VERSION ""

NS_ :

BS_:

BU_: CH DIPF DIPR ETH FC HVI HVS PARTY SDCV VEH VIRT

BO_ 962 VCLEFT_switchStatus: 8 CH
 SG_ VCLEFT_rearHVACButtonPressed m0 : 61|1@1+ (1,0) [0|1] ""  X
 SG_ VCLEFT_brakePressed m0 : 60|1@1+ (1,0) [0|1] ""  X
 SG_ VCLEFT_rearRightOccupancySwitch m0 : 58|2@1+ (1,0) [0|3] ""  X
 SG_ VCLEFT_rearLeftOccupancySwitch m0 : 56|2@1+ (1,0) [0|3] ""  X
 SG_ VCLEFT_rearCenterOccupancySwitch m0 : 54|2@1+ (1,0) [0|3] ""  X
 SG_ VCLEFT_rearLeftBuckleSwitch m0 : 52|2@1+ (1,0) [0|3] ""  X
 SG_ VCLEFT_frontOccupancySwitch m0 : 50|2@1+ (1,0) [0|3] ""  X
 SG_ VCLEFT_frontBuckleSwitch m0 : 48|2@1+ (1,0) [0|3] ""  ocs1p
 SG_ VCLEFT_btnWindowSwPackAutoDownRR m0 : 47|1@1+ (1,0) [0|1] ""  X
 SG_ VCLEFT_btnWindowSwPackDownRR m0 : 46|1@1+ (1,0) [0|1] ""  X
 SG_ VCLEFT_btnWindowSwPackAutoUpRR m0 : 45|1@1+ (1,0) [0|1] ""  X
 SG_ VCLEFT_btnWindowSwPackUpRR m0 : 44|1@1+ (1,0) [0|1] ""  X
 SG_ VCLEFT_btnWindowSwPackAutoDownRF m0 : 43|1@1+ (1,0) [0|1] ""  X
 SG_ VCLEFT_btnWindowSwPackDownRF m0 : 42|1@1+ (1,0) [0|1] ""  X
 SG_ VCLEFT_btnWindowSwPackAutoUpRF m0 : 41|1@1+ (1,0) [0|1] ""  X
 SG_ VCLEFT_btnWindowSwPackUpRF m0 : 40|1@1+ (1,0) [0|1] ""  X
 SG_ VCLEFT_btnWindowSwPackAutoDownLR m0 : 39|1@1+ (1,0) [0|1] ""  X
 SG_ VCLEFT_btnWindowSwPackDownLR m0 : 38|1@1+ (1,0) [0|1] ""  X
 SG_ VCLEFT_btnWindowSwPackAutoUpLR m0 : 37|1@1+ (1,0) [0|1] ""  X
 SG_ VCLEFT_btnWindowSwPackUpLR m0 : 36|1@1+ (1,0) [0|1] ""  X
 SG_ VCLEFT_btnWindowAutoDownLR m1 : 35|1@1+ (1,0) [0|1] ""  X
 SG_ VCLEFT_btnWindowSwPackAutoDownLF m0 : 35|1@1+ (1,0) [0|1] ""  X
 SG_ VCLEFT_btnWindowDownLR m1 : 34|1@1+ (1,0) [0|1] ""  X
 SG_ VCLEFT_btnWindowSwPackDownLF m0 : 34|1@1+ (1,0) [0|1] ""  X
 SG_ VCLEFT_btnWindowAutoUpLR m1 : 33|1@1+ (1,0) [0|1] ""  X
 SG_ VCLEFT_btnWindowSwPackAutoUpLF m0 : 33|1@1+ (1,0) [0|1] ""  X
 SG_ VCLEFT_btnWindowUpLR m1 : 32|1@1+ (1,0) [0|1] ""  X
 SG_ VCLEFT_btnWindowSwPackUpLF m0 : 32|1@1+ (1,0) [0|1] ""  X
 SG_ VCLEFT_frontSeatLumbarOut m0 : 30|2@1+ (1,0) [0|3] ""  X
 SG_ VCLEFT_frontSeatLumbarIn m0 : 28|2@1+ (1,0) [0|3] ""  X
 SG_ VCLEFT_frontSeatLumbarUp m0 : 26|2@1+ (1,0) [0|3] ""  X
 SG_ VCLEFT_swcRightScrollTicks m1 : 24|6@1- (1,0) [-32|31] ""  X
 SG_ VCLEFT_frontSeatLumbarDown m0 : 24|2@1+ (1,0) [0|3] ""  X
 SG_ VCLEFT_frontSeatBackrestForward m0 : 22|2@1+ (1,0) [0|3] ""  X
 SG_ VCLEFT_frontSeatBackrestBack m0 : 20|2@1+ (1,0) [0|3] ""  X
 SG_ VCLEFT_frontSeatLiftUp m0 : 18|2@1+ (1,0) [0|3] ""  X
 SG_ VCLEFT_frontSeatLiftDown m0 : 16|2@1+ (1,0) [0|3] ""  X
 SG_ VCLEFT_swcLeftScrollTicks m1 : 16|6@1- (1,0) [-32|31] ""  X
 SG_ VCLEFT_frontSeatTiltUp m0 : 14|2@1+ (1,0) [0|3] ""  X
 SG_ VCLEFT_swcLeftTiltLeft m1 : 14|2@1+ (1,0) [0|3] ""  X
 SG_ VCLEFT_swcRightPressed m1 : 12|2@1+ (1,0) [0|3] ""  X
 SG_ VCLEFT_frontSeatTiltDown m0 : 12|2@1+ (1,0) [0|3] ""  X
 SG_ VCLEFT_frontSeatTrackForward m0 : 10|2@1+ (1,0) [0|3] ""  X
 SG_ VCLEFT_swcRightTiltRight m1 : 10|2@1+ (1,0) [0|3] ""  X
 SG_ VCLEFT_swcRightTiltLeft m1 : 8|2@1+ (1,0) [0|3] ""  X
 SG_ VCLEFT_frontSeatTrackBack m0 : 8|2@1+ (1,0) [0|3] ""  X
 SG_ VCLEFT_swcLeftPressed m1 : 5|2@1+ (1,0) [0|3] ""  X
 SG_ VCLEFT_rightMirrorTilt m0 : 5|3@1+ (1,0) [0|4] ""  X
 SG_ VCLEFT_driverPresent m0 : 4|1@1+ (1,0) [0|1] ""  das
 SG_ VCLEFT_hazardButtonPressed m0 : 3|1@1+ (1,0) [0|1] ""  X
 SG_ VCLEFT_swcLeftTiltRight m1 : 3|2@1+ (1,0) [0|3] ""  X
 SG_ VCLEFT_hornSwitchPressed m0 : 2|1@1+ (1,0) [0|1] ""  X
 SG_ VCLEFT_switchStatusIndex M : 0|2@1+ (1,0) [0|2] ""  X

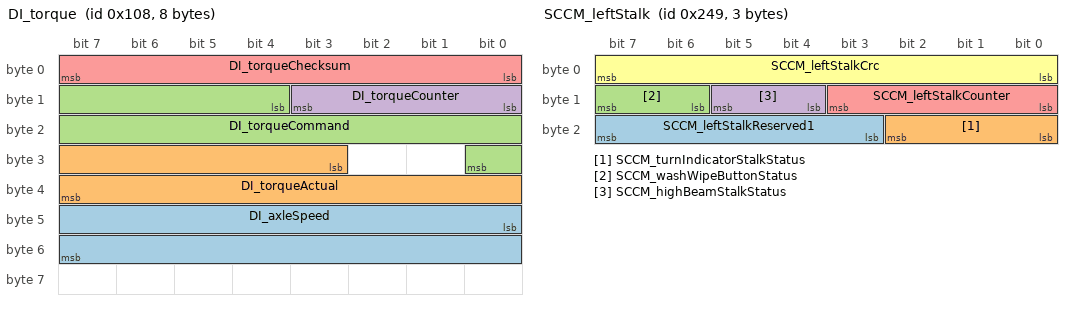
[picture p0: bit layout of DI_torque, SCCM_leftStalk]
BO_ 264 DI_torque: 8 CH
 SG_ DI_axleSpeed : 40|16@1- (0.1,0.0) [-2750|2750] "RPM"  epas3s
 SG_ DI_torqueActual : 27|13@1- (2,0) [-7500|7500] "Nm"  X
 SG_ DI_torqueCommand : 12|13@1- (2,0) [-7500|7500] "Nm"  X
 SG_ DI_torqueCounter : 8|4@1+ (1,0) [0|15] ""  epas3s
 SG_ DI_torqueChecksum : 0|8@1+ (1,0) [0|255] ""  epas3s

BO_ 921 DAS_status: 8 CH
 SG_ DAS_statusChecksum : 56|8@1+ (1,0) [0|255] ""  aps
 SG_ DAS_statusCounter : 52|4@1+ (1,0) [0|15] ""  aps
 SG_ DAS_summonAvailable : 51|1@1+ (1,0) [0|1] ""  aps
 SG_ DAS_autoLaneChangeState : 46|5@1+ (1,0) [0|31] ""  aps
 SG_ DAS_autopilotHandsOnState : 42|4@1+ (1,0) [0|15] ""  aps
 SG_ DAS_fleetSpeedState : 40|2@1+ (1,0) [0|3] ""  aps
 SG_ DAS_laneDepartureWarning : 37|3@1+ (1,0) [0|5] ""  aps
 SG_ DAS_csaState : 35|2@1+ (1,0) [0|3] ""  aps
 SG_ DAS_sideCollisionInhibit : 34|1@1+ (1,0) [0|1] ""  aps
 SG_ DAS_sideCollisionWarning : 32|2@1+ (1,0) [0|3] ""  aps
 SG_ DAS_sideCollisionAvoid : 30|2@1+ (1,0) [0|3] ""  aps
 SG_ DAS_summonRvsLeashReached : 29|1@1+ (1,0) [0|1] ""  aps
 SG_ DAS_summonFwdLeashReached : 28|1@1+ (1,0) [0|1] ""  aps
 SG_ DAS_autoparkWaitingForBrake : 26|1@1+ (1,0) [0|1] ""  gtw
 SG_ DAS_autoParked : 25|1@1+ (1,0) [0|1] ""  aps
 SG_ DAS_autoparkReady : 24|1@1+ (1,0) [0|1] ""  aps
 SG_ DAS_forwardCollisionWarning : 22|2@1+ (1,0) [0|3] ""  aps
 SG_ DAS_heaterState : 21|1@1+ (1,0) [0|1] ""  gtw
 SG_ DAS_visionOnlySpeedLimit : 16|5@1+ (5,0) [0|150] "kph/mph"  aps
 SG_ DAS_summonClearedGate : 15|1@1+ (1,0) [0|1] ""  aps
 SG_ DAS_summonObstacle : 14|1@1+ (1,0) [0|1] ""  aps
 SG_ DAS_suppressSpeedWarning : 13|1@1+ (1,0) [0|1] ""  aps
 SG_ DAS_fusedSpeedLimit : 8|5@1+ (5,0) [0|150] "kph/mph"  aps
 SG_ DAS_blindSpotRearRight : 6|2@1+ (1,0) [0|3] ""  aps
 SG_ DAS_blindSpotRearLeft : 4|2@1+ (1,0) [0|3] ""  aps
 SG_ DAS_autopilotState : 0|4@1+ (1,0) [0|15] ""  aps

BO_ 585 SCCM_leftStalk: 3 CH
 SG_ SCCM_leftStalkReserved1 : 19|5@1+ (1,0) [0|31] ""  X
 SG_ SCCM_turnIndicatorStalkStatus : 16|3@1+ (1,0) [0|5] ""  park
 SG_ SCCM_washWipeButtonStatus : 14|2@1+ (1,0) [0|3] ""  X
 SG_ SCCM_highBeamStalkStatus : 12|2@1+ (1,0) [0|3] ""  X
 SG_ SCCM_leftStalkCounter : 8|4@1+ (1,0) [0|15] ""  X
 SG_ SCCM_leftStalkCrc : 0|8@1+ (1,0) [0|255] ""  X

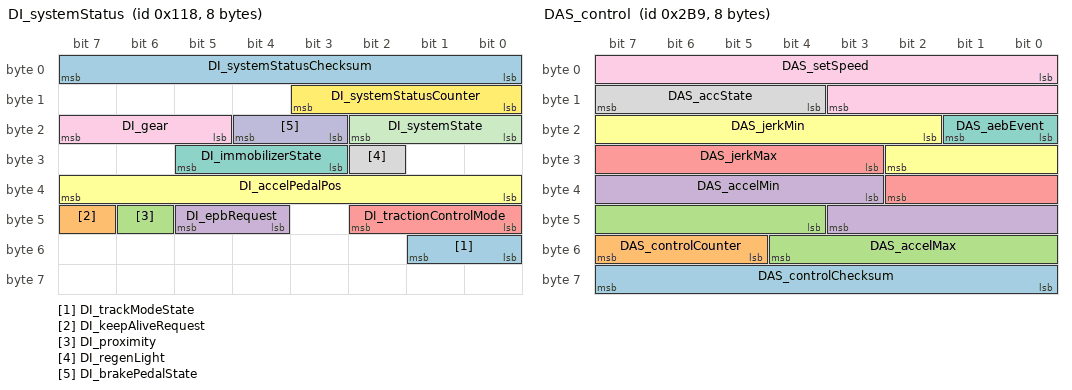
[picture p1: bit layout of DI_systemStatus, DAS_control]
BO_ 280 DI_systemStatus: 8 CH
 SG_ DI_trackModeState : 48|2@1+ (1,0) [0|2] ""  X
 SG_ DI_keepAliveRequest : 47|1@1+ (1,0) [0|1] ""  X
 SG_ DI_proximity : 46|1@1+ (1,0) [0|1] ""  X
 SG_ DI_epbRequest : 44|2@1+ (1,0) [0|2] ""  X
 SG_ DI_tractionControlMode : 40|3@1+ (1,0) [0|5] ""  X
 SG_ DI_accelPedalPos : 32|8@1+ (0.4,0) [0|100] "%"  X
 SG_ DI_immobilizerState : 27|3@1+ (1,0) [0|6] ""  X
 SG_ DI_regenLight : 26|1@1+ (1,0) [0|1] ""  X
 SG_ DI_gear : 21|3@1+ (1,0) [0|7] ""  park
 SG_ DI_brakePedalState : 19|2@1+ (1,0) [0|2] ""  X
 SG_ DI_systemState : 16|3@1+ (1,0) [0|5] ""  X
 SG_ DI_systemStatusCounter : 8|4@1+ (1,0) [0|15] ""  X
 SG_ DI_systemStatusChecksum : 0|8@1+ (1,0) [0|255] ""  X

BO_ 697 DAS_control: 8 CH
 SG_ DAS_controlChecksum : 56|8@1+ (1,0) [0|255] ""  aps
 SG_ DAS_controlCounter : 53|3@1+ (1,0) [0|7] ""  aps
 SG_ DAS_accelMax : 44|9@1+ (0.04,-15) [-15|5.44] "m/s^2"  aps
 SG_ DAS_accelMin : 35|9@1+ (0.04,-15) [-15|5.44] "m/s^2"  aps
 SG_ DAS_jerkMax : 27|8@1+ (0.034,0) [0|8.67] "m/s^3"  aps
 SG_ DAS_jerkMin : 18|9@1+ (0.018,-9.1) [-9.1|0.097999999999999] "m/s^3"  aps
 SG_ DAS_aebEvent : 16|2@1+ (1,0) [0|3] ""  aps
 SG_ DAS_accState : 12|4@1+ (1,0) [0|15] ""  aps
 SG_ DAS_setSpeed : 0|12@1+ (0.1,0) [0|409.4] "kph"  aps

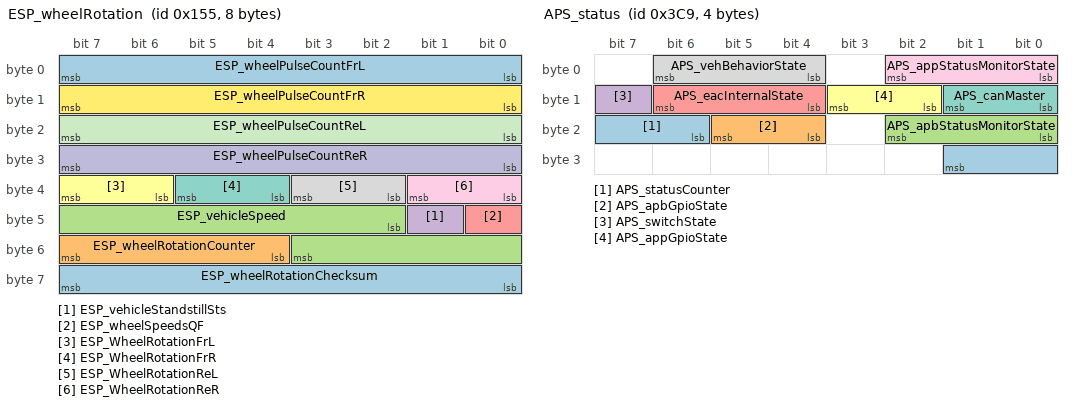
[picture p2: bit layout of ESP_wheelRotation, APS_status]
BO_ 341 ESP_wheelRotation: 8 CH
 SG_ ESP_wheelRotationChecksum : 56|8@1+ (1,0) [0|255] ""  app
 SG_ ESP_wheelRotationCounter : 52|4@1+ (1,0) [0|15] ""  app
 SG_ ESP_vehicleSpeed : 42|10@1+ (0.5,0) [0|511] "kph"  app
 SG_ ESP_vehicleStandstillSts : 41|1@1+ (1,0) [0|1] ""  park
 SG_ ESP_wheelSpeedsQF : 40|1@1+ (1,0) [0|1] ""  epas3s
 SG_ ESP_WheelRotationFrL : 38|2@1+ (1,0) [0|3] ""  aps
 SG_ ESP_WheelRotationFrR : 36|2@1+ (1,0) [0|3] ""  aps
 SG_ ESP_WheelRotationReL : 34|2@1+ (1,0) [0|3] ""  aps
 SG_ ESP_WheelRotationReR : 32|2@1+ (1,0) [0|3] ""  aps
 SG_ ESP_wheelPulseCountReR : 24|8@1+ (1,0) [0|254] "1"  das
 SG_ ESP_wheelPulseCountReL : 16|8@1+ (1,0) [0|254] "1"  das
 SG_ ESP_wheelPulseCountFrR : 8|8@1+ (1,0) [0|254] "1"  app
 SG_ ESP_wheelPulseCountFrL : 0|8@1+ (1,0) [0|254] "1"  app

BO_ 969 APS_status: 4 CH
 SG_ APS_statusCounter : 22|4@1+ (1,0) [0|15] ""  X
 SG_ APS_apbGpioState : 20|2@1+ (1,0) [0|3] ""  gtw
 SG_ APS_apbStatusMonitorState : 16|3@1+ (1,0) [0|7] ""  gtw
 SG_ APS_switchState : 15|1@1+ (1,0) [0|1] ""  X
 SG_ APS_eacInternalState : 12|3@1+ (1,0) [0|7] ""  gtw
 SG_ APS_appGpioState : 10|2@1+ (1,0) [0|3] ""  gtw
 SG_ APS_canMaster : 8|2@1+ (1,0) [0|3] ""  gtw
 SG_ APS_vehBehaviorState : 4|3@1+ (1,0) [0|7] ""  gtw
 SG_ APS_appStatusMonitorState : 0|3@1+ (1,0) [0|7] ""  gtw

BO_ 737 VCFRONT_status: 8 CH
 SG_ VCFRONT_frunkAccessPost m0 : 62|1@1+ (1,0) [0|1] ""  X
 SG_ VCFRONT_headlampRightFanStatus m0 : 61|1@1+ (1,0) [0|1] ""  X
 SG_ VCFRONT_headlampLeftFanStatus m0 : 60|1@1+ (1,0) [0|1] ""  X
 SG_ VCFRONT_12VOverchargeCounter m4 : 59|4@1+ (1,0) [0|15] ""  X
 SG_ VCFRONT_sleepCurrent m1 : 53|10@1- (1,0) [-512|511] "mA"  X
 SG_ VCFRONT_wiperPositionDeg m0 : 52|8@1+ (1,0) [0|255] "deg"  X
 SG_ VCFRONT_hornOn m0 : 51|1@1+ (1,0) [0|1] ""  X
 SG_ VCFRONT_anyDoorOpen m0 : 50|1@1+ (1,0) [0|1] ""  tas
 SG_ VCFRONT_anyClosureOpen m0 : 49|1@1+ (1,0) [0|1] ""  tas
 SG_ VCFRONT_wiperCycles m3 : 48|16@1+ (100,0) [0|6553500] "Cycles"  X
 SG_ VCFRONT_homelinkCommStatus m2 : 48|2@1+ (1,0) [0|3] ""  X
 SG_ VCFRONT_frunkInteriorRelSwitch m0 : 48|1@1+ (1,0) [0|1] ""  X
 SG_ VCFRONT_timeSpentSleeping m1 : 45|8@1+ (1,0) [0|255] "s"  X
 SG_ VCFRONT_IBSUnfilteredTemperature m4 : 43|16@1- (0.01,0) [-327.68|327.67] "degC"  X
 SG_ VCFRONT_HSDInitCompleteU16 m4 : 42|1@1+ (1,0) [0|1] ""  X
 SG_ VCFRONT_HSDInitCompleteU13 m4 : 41|1@1+ (1,0) [0|1] ""  X
 SG_ VCFRONT_PEResetLineState m4 : 40|1@1+ (1,0) [0|1] ""  X
 SG_ VCFRONT_pressureRefrigDischarge m3 : 40|8@1+ (0.125,0) [0|31.75] "bar"  X
 SG_ VCFRONT_homelinkV2Response4 m2 : 40|8@1+ (1,0) [0|255] ""  X
 SG_ VCFRONT_IBSFault m4 : 39|1@1+ (1,0) [0|1] ""  X
 SG_ VCFRONT_PCSMia m4 : 38|1@1+ (1,0) [0|1] ""  X
 SG_ VCFRONT_headlightRightVPosition m0 : 38|10@1+ (1,0) [0|1023] "ticks"  X
 SG_ VCFRONT_chargeNeeded m4 : 37|1@1+ (1,0) [0|1] ""  X
 SG_ VCFRONT_timeSpentDischarging m1 : 35|10@1+ (1,0) [0|1023] "min"  X
 SG_ VCFRONT_pressureRefrigSuction m3 : 32|7@1+ (0.125,0) [0|11.5] "bar"  X
 SG_ VCFRONT_homelinkV2Response3 m2 : 32|8@1+ (1,0) [0|255] ""  X
 SG_ VCFRONT_hasLowRefrigerant m3 : 29|1@1+ (1,0) [0|1] ""  X
 SG_ VCFRONT_headlightLeftVPosition m0 : 28|10@1+ (1,0) [0|1023] "ticks"  X
 SG_ VCFRONT_compPerfRecoveryLimited m3 : 27|1@1+ (1,0) [0|1] ""  X
 SG_ VCFRONT_chillerDemandActive m3 : 26|1@1+ (1,0) [0|1] ""  X
 SG_ VCFRONT_timeSpentCharging m1 : 25|10@1+ (1,0) [0|1023] "min"  X
 SG_ VCFRONT_isEvapOperationAllowed m3 : 25|1@1+ (1,0) [0|1] ""  X
 SG_ VCFRONT_airCompressorStatus m0 : 25|3@1+ (1,0) [0|7] ""  tas
 SG_ VCFRONT_AS8510Voltage m4 : 25|12@1+ (0.005443676098,0) [0|22.28641] "V"  X
 SG_ VCFRONT_crashUnlockOverrideSet m0 : 24|1@1+ (1,0) [0|1] ""  X
 SG_ VCFRONT_freezeEvapITerm m3 : 24|1@1+ (1,0) [0|1] ""  X
 SG_ VCFRONT_homelinkV2Response2 m2 : 24|8@1+ (1,0) [0|255] ""  X
 SG_ VCFRONT_crashState m0 : 22|2@1+ (1,0) [0|2] ""  X
 SG_ VCFRONT_batterySMState m1 : 22|3@1+ (1,0) [0|7] ""  X
 SG_ VCFRONT_reverseBatteryFault m1 : 21|1@1+ (1,0) [0|1] ""  X
 SG_ VCFRONT_crashDetectedType m0 : 20|2@1+ (1,0) [0|2] ""  X
 SG_ VCFRONT_vehicleStatusDBG m1 : 16|5@1+ (1,0) [0|17] ""  X
 SG_ VCFRONT_wiperState m0 : 16|4@1+ (1,0) [0|12] ""  das
 SG_ VCFRONT_homelinkV2Response1 m2 : 16|8@1+ (1,0) [0|255] ""  X
 SG_ VCFRONT_minEvapHeatRejection m3 : 16|8@1+ (10,0) [0|2500] "W"  X
 SG_ VCFRONT_vbatMonitorVoltage m4 : 13|12@1+ (0.005443676098,0) [0|22.28641] "V"  X
 SG_ VCFRONT_iBoosterStateDBG m1 : 12|3@1+ (1,0) [0|4] ""  X
 SG_ VCFRONT_wiperPosition m0 : 12|3@1+ (1,0) [0|4] ""  X
 SG_ VCFRONT_epasWakeLine m1 : 11|1@1+ (1,0) [0|1] ""  X
 SG_ VCFRONT_iBoosterWakeLine m1 : 10|1@1+ (1,0) [0|1] ""  X
 SG_ VCFRONT_ChargePumpVoltageStable m1 : 9|1@1+ (1,0) [0|1] ""  X
 SG_ VCFRONT_homelinkV2Response0 m2 : 8|8@1+ (1,0) [0|255] ""  X
 SG_ VCFRONT_railBState m1 : 8|1@1+ (1,0) [0|1] ""  X
 SG_ VCFRONT_maxEvapHeatRejection m3 : 8|8@1+ (32,0) [0|8000] "W"  X
 SG_ VCFRONT_wiperSpeed m0 : 8|4@1+ (1,0) [0|8] ""  das
 SG_ VCFRONT_railAState m1 : 7|1@1+ (1,0) [0|1] ""  X
 SG_ VCFRONT_12VBRailStable m1 : 6|1@1+ (1,0) [0|1] ""  X
 SG_ VCFRONT_12VARailStable m1 : 5|1@1+ (1,0) [0|1] ""  X
 SG_ VCFRONT_5VBRailStable m1 : 4|1@1+ (1,0) [0|1] ""  X
 SG_ VCFRONT_frunkLatchStatus m0 : 3|4@1+ (1,0) [0|8] ""  X
 SG_ VCFRONT_tempCompTargetVoltage m4 : 3|10@1+ (0.01,9) [9|16] "V"  X
 SG_ VCFRONT_5VARailStable m1 : 3|1@1+ (1,0) [0|1] ""  X
 SG_ VCFRONT_statusIndex M : 0|3@1+ (1,0) [0|5] ""  X

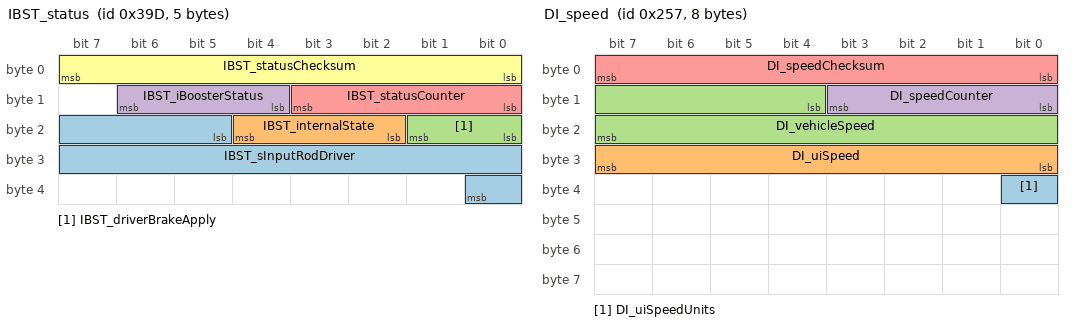
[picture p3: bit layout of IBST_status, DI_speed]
BO_ 925 IBST_status: 5 CH
 SG_ IBST_sInputRodDriver : 21|12@1+ (0.015625,-5) [-5|47] "mm"  gtw
 SG_ IBST_internalState : 18|3@1+ (1,0) [0|6] ""  gtw
 SG_ IBST_driverBrakeApply : 16|2@1+ (1,0) [0|3] ""  gtw
 SG_ IBST_iBoosterStatus : 12|3@1+ (1,0) [0|6] ""  gtw
 SG_ IBST_statusCounter : 8|4@1+ (1,0) [0|15] ""  X
 SG_ IBST_statusChecksum : 0|8@1+ (1,0) [0|255] ""  X

BO_ 599 DI_speed: 8 CH
 SG_ DI_uiSpeedUnits : 32|1@1+ (1,0) [0|1] ""  das
 SG_ DI_uiSpeed : 24|8@1+ (1,0) [0|254] ""  das
 SG_ DI_vehicleSpeed : 12|12@1+ (0.08,-40) [-40|285] "kph"  park
 SG_ DI_speedCounter : 8|4@1+ (1,0) [0|15] ""  park
 SG_ DI_speedChecksum : 0|8@1+ (1,0) [0|255] ""  park

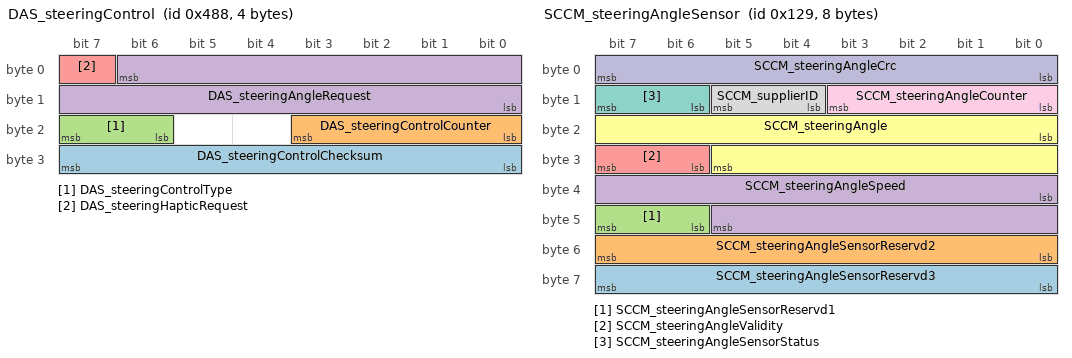
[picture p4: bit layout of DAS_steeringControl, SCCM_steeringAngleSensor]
BO_ 1160 DAS_steeringControl: 4 CH
 SG_ DAS_steeringControlChecksum : 31|8@0+ (1,0) [0|255] ""  aps
 SG_ DAS_steeringControlCounter : 19|4@0+ (1,0) [0|15] ""  aps
 SG_ DAS_steeringControlType : 23|2@0+ (1,0) [0|3] ""  aps
 SG_ DAS_steeringAngleRequest : 6|15@0+ (0.1,-1638.35) [-1638.35|1638.35] "deg"  aps
 SG_ DAS_steeringHapticRequest : 7|1@0+ (1,0) [0|1] ""  aps

BO_ 297 SCCM_steeringAngleSensor: 8 CH
 SG_ SCCM_steeringAngleSensorReservd3 : 56|8@1+ (1,0) [0|255] ""  X
 SG_ SCCM_steeringAngleSensorReservd2 : 48|8@1+ (1,0) [0|255] ""  X
 SG_ SCCM_steeringAngleSensorReservd1 : 46|2@1+ (1,0) [0|3] ""  X
 SG_ SCCM_steeringAngleSpeed : 32|14@1+ (0.5,-4096) [-4096|4095.5] "deg/s"  park
 SG_ SCCM_steeringAngleValidity : 30|2@1+ (1,0) [0|3] ""  park
 SG_ SCCM_steeringAngle : 16|14@1+ (0.1,-819.2) [-819.2|819] "deg"  epas3s
 SG_ SCCM_steeringAngleSensorStatus : 14|2@1+ (1,0) [0|3] ""  epas3s
 SG_ SCCM_supplierID : 12|2@1+ (1,0) [0|3] ""  park
 SG_ SCCM_steeringAngleCounter : 8|4@1+ (1,0) [0|15] ""  epas3s
 SG_ SCCM_steeringAngleCrc : 0|8@1+ (1,0) [0|255] ""  epas3s

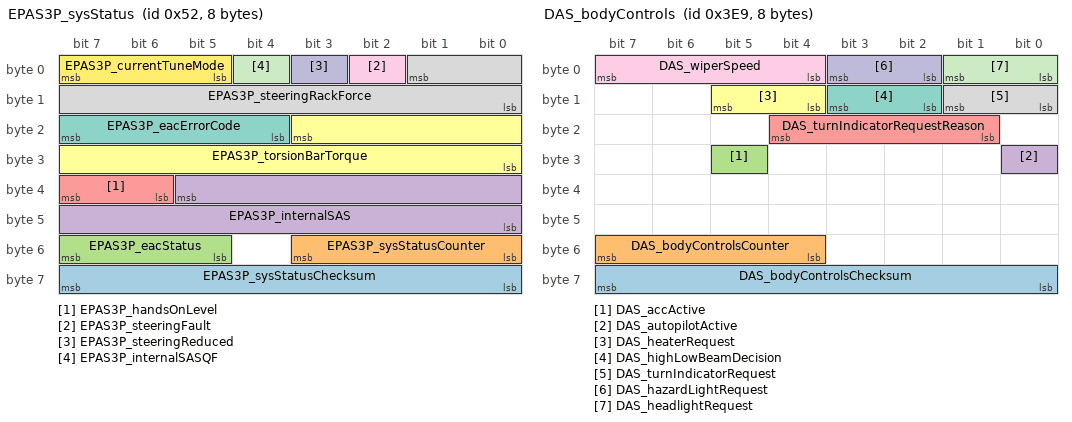
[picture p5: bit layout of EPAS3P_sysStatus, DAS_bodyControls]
BO_ 82 EPAS3P_sysStatus: 8 CH
 SG_ EPAS3P_sysStatusChecksum : 63|8@0+ (1,0) [0|255] ""  park
 SG_ EPAS3P_sysStatusCounter : 51|4@0+ (1,0) [0|15] ""  park
 SG_ EPAS3P_eacStatus : 55|3@0+ (1,0) [0|7] ""  park
 SG_ EPAS3P_internalSAS : 37|14@0+ (0.1,-819.2) [-819.2|819] "deg"  park
 SG_ EPAS3P_handsOnLevel : 39|2@0+ (1,0) [0|3] ""  park
 SG_ EPAS3P_torsionBarTorque : 19|12@0+ (0.01,-20.5) [-20.5|20.45] "Nm"  park
 SG_ EPAS3P_eacErrorCode : 23|4@0+ (1,0) [0|15] ""  park
 SG_ EPAS3P_steeringRackForce : 1|10@0+ (50,-25575) [-25575|25575] "N"  park
 SG_ EPAS3P_steeringFault : 2|1@0+ (1,0) [0|1] ""  park
 SG_ EPAS3P_steeringReduced : 3|1@0+ (1,0) [0|1] ""  park
 SG_ EPAS3P_internalSASQF : 4|1@0+ (1,0) [0|1] ""  park
 SG_ EPAS3P_currentTuneMode : 7|3@0+ (1,0) [0|5] ""  park

BO_ 1001 DAS_bodyControls: 8 VEH
 SG_ DAS_bodyControlsChecksum : 56|8@1+ (1,0) [0|255] ""  aps
 SG_ DAS_bodyControlsCounter : 52|4@1+ (1,0) [0|15] ""  aps
 SG_ DAS_accActive : 29|1@1+ (1,0) [0|1] ""  XXX
 SG_ DAS_autopilotActive : 24|1@1+ (1,0) [0|1] ""  XXX
 SG_ DAS_turnIndicatorRequestReason : 17|4@1+ (1,0) [0|8] ""  aps
 SG_ DAS_heaterRequest : 12|2@1+ (1,0) [0|2] ""  aps
 SG_ DAS_highLowBeamDecision : 10|2@1+ (1,0) [0|3] ""  aps
 SG_ DAS_turnIndicatorRequest : 8|2@1+ (1,0) [0|3] ""  aps
 SG_ DAS_wiperSpeed : 4|4@1+ (1,0) [0|15] ""  aps
 SG_ DAS_hazardLightRequest : 2|2@1+ (1,0) [0|3] ""  aps
 SG_ DAS_headlightRequest : 0|2@1+ (1,0) [0|3] ""  aps

BO_ 1013 ID3F5VCFRONT_lighting: 8 VehicleBus
 SG_ VCFRONT_lowBeamsCalibrated : 62|1@1+ (1,0) [0|1] ""  Receiver
 SG_ VCFRONT_lowBeamsOnForDRL : 61|1@1+ (1,0) [0|1] ""  Receiver
 SG_ VCFRONT_simLatchingStalk : 59|2@1+ (1,0) [0|3] ""  Receiver
 SG_ VCFRONT_highBeamSwitchActive : 58|1@1+ (1,0) [0|1] ""  Receiver
 SG_ VCFRONT_parkRightStatus : 56|2@1+ (1,0) [0|3] ""  Receiver
 SG_ VCFRONT_parkLeftStatus : 54|2@1+ (1,0) [0|3] ""  Receiver
 SG_ VCFRONT_turnSignalRightStatus : 52|2@1+ (1,0) [0|3] ""  Receiver
 SG_ VCFRONT_turnSignalLeftStatus : 50|2@1+ (1,0) [0|3] ""  Receiver
 SG_ VCFRONT_sideRepeaterRightStatus : 48|2@1+ (1,0) [0|3] ""  Receiver
 SG_ VCFRONT_sideRepeaterLeftStatus : 46|2@1+ (1,0) [0|3] ""  Receiver
 SG_ VCFRONT_sideMarkersStatus : 44|2@1+ (1,0) [0|3] ""  Receiver
 SG_ VCFRONT_fogRightStatus : 42|2@1+ (1,0) [0|3] ""  Receiver
 SG_ VCFRONT_fogLeftStatus : 40|2@1+ (1,0) [0|3] ""  Receiver
 SG_ VCFRONT_DRLRightStatus : 38|2@1+ (1,0) [0|3] ""  Receiver
 SG_ VCFRONT_DRLLeftStatus : 36|2@1+ (1,0) [0|3] ""  Receiver
 SG_ VCFRONT_highBeamRightStatus : 34|2@1+ (1,0) [0|3] ""  Receiver
 SG_ VCFRONT_highBeamLeftStatus : 32|2@1+ (1,0) [0|3] ""  Receiver
 SG_ VCFRONT_lowBeamRightStatus : 30|2@1+ (1,0) [0|3] ""  Receiver
 SG_ VCFRONT_lowBeamLeftStatus : 28|2@1+ (1,0) [0|3] ""  Receiver
 SG_ VCFRONT_hazardSwitchBacklight : 27|1@1+ (1,0) [0|1] ""  Receiver
 SG_ VCFRONT_seeYouHomeLightingReq : 26|1@1+ (1,0) [0|1] ""  Receiver
 SG_ VCFRONT_approachLightingRequest : 25|1@1+ (1,0) [0|1] ""  Receiver
 SG_ VCFRONT_courtesyLightingRequest : 24|1@1+ (1,0) [0|1] ""  Receiver
 SG_ VCFRONT_switchLightingBrightness : 16|8@1+ (0.5,0) [0|127] "%"  Receiver
 SG_ VCFRONT_ambientLightingBrightnes : 8|8@1+ (0.5,0) [0|127] "%"  Receiver
 SG_ VCFRONT_hazardLightRequest : 4|4@1+ (1,0) [0|8] ""  Receiver
 SG_ VCFRONT_indicatorRightRequest : 2|2@1+ (1,0) [0|2] ""  Receiver
 SG_ VCFRONT_indicatorLeftRequest : 0|2@1+ (1,0) [0|2] ""  Receiver

VAL_ 962 VCLEFT_rearRightOccupancySwitch 2 "SWITCH_ON" 0 "SWITCH_SNA" 3 "SWITCH_FAULT" 1 "SWITCH_OFF" ;
VAL_ 962 VCLEFT_rearLeftOccupancySwitch 2 "SWITCH_ON" 0 "SWITCH_SNA" 3 "SWITCH_FAULT" 1 "SWITCH_OFF" ;
VAL_ 962 VCLEFT_rearCenterOccupancySwitch 2 "SWITCH_ON" 0 "SWITCH_SNA" 3 "SWITCH_FAULT" 1 "SWITCH_OFF" ;
VAL_ 962 VCLEFT_rearLeftBuckleSwitch 2 "SWITCH_ON" 0 "SWITCH_SNA" 3 "SWITCH_FAULT" 1 "SWITCH_OFF" ;
VAL_ 962 VCLEFT_frontOccupancySwitch 2 "SWITCH_ON" 0 "SWITCH_SNA" 3 "SWITCH_FAULT" 1 "SWITCH_OFF" ;
VAL_ 962 VCLEFT_frontBuckleSwitch 2 "SWITCH_ON" 0 "SWITCH_SNA" 3 "SWITCH_FAULT" 1 "SWITCH_OFF" ;
VAL_ 962 VCLEFT_frontSeatLumbarOut 2 "SWITCH_ON" 0 "SWITCH_SNA" 3 "SWITCH_FAULT" 1 "SWITCH_OFF" ;
VAL_ 962 VCLEFT_frontSeatLumbarIn 2 "SWITCH_ON" 0 "SWITCH_SNA" 3 "SWITCH_FAULT" 1 "SWITCH_OFF" ;
VAL_ 962 VCLEFT_frontSeatLumbarUp 2 "SWITCH_ON" 0 "SWITCH_SNA" 3 "SWITCH_FAULT" 1 "SWITCH_OFF" ;
VAL_ 962 VCLEFT_frontSeatLumbarDown 2 "SWITCH_ON" 0 "SWITCH_SNA" 3 "SWITCH_FAULT" 1 "SWITCH_OFF" ;
VAL_ 962 VCLEFT_frontSeatBackrestForward 2 "SWITCH_ON" 0 "SWITCH_SNA" 3 "SWITCH_FAULT" 1 "SWITCH_OFF" ;
VAL_ 962 VCLEFT_frontSeatBackrestBack 2 "SWITCH_ON" 0 "SWITCH_SNA" 3 "SWITCH_FAULT" 1 "SWITCH_OFF" ;
VAL_ 962 VCLEFT_frontSeatLiftUp 2 "SWITCH_ON" 0 "SWITCH_SNA" 3 "SWITCH_FAULT" 1 "SWITCH_OFF" ;
VAL_ 962 VCLEFT_frontSeatLiftDown 2 "SWITCH_ON" 0 "SWITCH_SNA" 3 "SWITCH_FAULT" 1 "SWITCH_OFF" ;
VAL_ 962 VCLEFT_frontSeatTiltUp 2 "SWITCH_ON" 0 "SWITCH_SNA" 3 "SWITCH_FAULT" 1 "SWITCH_OFF" ;
VAL_ 962 VCLEFT_swcLeftTiltLeft 2 "SWITCH_ON" 0 "SWITCH_SNA" 3 "SWITCH_FAULT" 1 "SWITCH_OFF" ;
VAL_ 962 VCLEFT_swcRightPressed 2 "SWITCH_ON" 0 "SWITCH_SNA" 3 "SWITCH_FAULT" 1 "SWITCH_OFF" ;
VAL_ 962 VCLEFT_frontSeatTiltDown 2 "SWITCH_ON" 0 "SWITCH_SNA" 3 "SWITCH_FAULT" 1 "SWITCH_OFF" ;
VAL_ 962 VCLEFT_frontSeatTrackForward 2 "SWITCH_ON" 0 "SWITCH_SNA" 3 "SWITCH_FAULT" 1 "SWITCH_OFF" ;
VAL_ 962 VCLEFT_swcRightTiltRight 2 "SWITCH_ON" 0 "SWITCH_SNA" 3 "SWITCH_FAULT" 1 "SWITCH_OFF" ;
VAL_ 962 VCLEFT_swcRightTiltLeft 2 "SWITCH_ON" 0 "SWITCH_SNA" 3 "SWITCH_FAULT" 1 "SWITCH_OFF" ;
VAL_ 962 VCLEFT_frontSeatTrackBack 2 "SWITCH_ON" 0 "SWITCH_SNA" 3 "SWITCH_FAULT" 1 "SWITCH_OFF" ;
VAL_ 962 VCLEFT_swcLeftPressed 2 "SWITCH_ON" 0 "SWITCH_SNA" 3 "SWITCH_FAULT" 1 "SWITCH_OFF" ;
VAL_ 962 VCLEFT_rightMirrorTilt 4 "MIRROR_TILT_LEFT" 2 "MIRROR_TILT_UP" 3 "MIRROR_TILT_RIGHT" 0 "MIRROR_TILT_STOP" 1 "MIRROR_TILT_DOWN" ;
VAL_ 962 VCLEFT_swcLeftTiltRight 2 "SWITCH_ON" 0 "SWITCH_SNA" 3 "SWITCH_FAULT" 1 "SWITCH_OFF" ;
VAL_ 962 VCLEFT_switchStatusIndex 1 "VCLEFT_SWITCH_STATUS_INDEX_1" 2 "VCLEFT_SWITCH_STATUS_INDEX_INVALID" 0 "VCLEFT_SWITCH_STATUS_INDEX_0" ;
VAL_ 264 DI_axleSpeed -32768 "SNA" ;
VAL_ 264 DI_torqueActual -4096 "SNA" ;
VAL_ 264 DI_torqueCommand -4096 "SNA" ;
VAL_ 921 DAS_autoLaneChangeState 5 "ALC_UNAVAILABLE_VEHICLE_SPEED" 17 "ALC_ABORT_POOR_VIEW_RANGE" 23 "ALC_BLOCKED_VEH_TTC_AND_USS_L" 0 "ALC_UNAVAILABLE_DISABLED" 26 "ALC_BLOCKED_LANE_TYPE_L" 29 "ALC_ABORT_TIMEOUT" 9 "ALC_IN_PROGRESS_L" 4 "ALC_UNAVAILABLE_EXITING_HIGHWAY" 22 "ALC_BLOCKED_VEH_TTC_L" 12 "ALC_WAITING_FOR_SIDE_OBST_TO_PASS_R" 18 "ALC_ABORT_LC_HEALTH_BAD" 28 "ALC_WAITING_HANDS_ON" 8 "ALC_AVAILABLE_BOTH" 11 "ALC_WAITING_FOR_SIDE_OBST_TO_PASS_L" 3 "ALC_UNAVAILABLE_TP_FOLLOW" 2 "ALC_UNAVAILABLE_SONICS_INVALID" 21 "ALC_UNAVAILABLE_SOLID_LANE_LINE" 24 "ALC_BLOCKED_VEH_TTC_R" 1 "ALC_UNAVAILABLE_NO_LANES" 25 "ALC_BLOCKED_VEH_TTC_AND_USS_R" 30 "ALC_ABORT_MISSION_PLAN_INVALID" 27 "ALC_BLOCKED_LANE_TYPE_R" 19 "ALC_ABORT_BLINKER_TURNED_OFF" 31 "ALC_SNA" 13 "ALC_WAITING_FOR_FWD_OBST_TO_PASS_L" 16 "ALC_ABORT_SIDE_OBSTACLE_PRESENT_R" 6 "ALC_AVAILABLE_ONLY_L" 20 "ALC_ABORT_OTHER_REASON" 15 "ALC_ABORT_SIDE_OBSTACLE_PRESENT_L" 7 "ALC_AVAILABLE_ONLY_R" 14 "ALC_WAITING_FOR_FWD_OBST_TO_PASS_R" 10 "ALC_IN_PROGRESS_R" ;
VAL_ 921 DAS_autopilotHandsOnState 8 "LC_HANDS_ON_SUSPENDED" 15 "LC_HANDS_ON_SNA" 7 "LC_HANDS_ON_REQD_STRUCK_OUT" 3 "LC_HANDS_ON_REQD_VISUAL" 4 "LC_HANDS_ON_REQD_CHIME_1" 6 "LC_HANDS_ON_REQD_SLOWING" 1 "LC_HANDS_ON_REQD_DETECTED" 2 "LC_HANDS_ON_REQD_NOT_DETECTED" 5 "LC_HANDS_ON_REQD_CHIME_2" 0 "LC_HANDS_ON_NOT_REQD" ;
VAL_ 921 DAS_fleetSpeedState 0 "FLEETSPEED_UNAVAILABLE" 1 "FLEETSPEED_AVAILABLE" 2 "FLEETSPEED_ACTIVE" 3 "FLEETSPEED_HOLD" ;
VAL_ 921 DAS_laneDepartureWarning 5 "SNA" 0 "NONE" 2 "RIGHT_WARNING" 4 "RIGHT_WARNING_SEVERE" 3 "LEFT_WARNING_SEVERE" 1 "LEFT_WARNING" ;
VAL_ 921 DAS_csaState 1 "CSA_EXTERNAL_STATE_AVAILABLE" 3 "CSA_EXTERNAL_STATE_HOLD" 2 "CSA_EXTERNAL_STATE_ENABLE" 0 "CSA_EXTERNAL_STATE_UNAVAILABLE" ;
VAL_ 921 DAS_sideCollisionInhibit 0 "NO_INHIBIT" 1 "INHIBIT" ;
VAL_ 921 DAS_sideCollisionWarning 0 "NONE" 2 "WARN_RIGHT" 1 "WARN_LEFT" 3 "WARN_LEFT_RIGHT" ;
VAL_ 921 DAS_sideCollisionAvoid 3 "SNA" 0 "NONE" 1 "AVOID_LEFT" 2 "AVOID_RIGHT" ;
VAL_ 921 DAS_autoparkReady 0 "AUTOPARK_UNAVAILABLE" 1 "AUTOPARK_READY" ;
VAL_ 921 DAS_forwardCollisionWarning 3 "SNA" 0 "NONE" 1 "FORWARD_COLLISION_WARNING" ;
VAL_ 921 DAS_heaterState 0 "HEATER_OFF_SNA" 1 "HEATER_ON" ;
VAL_ 921 DAS_visionOnlySpeedLimit 31 "NONE" 0 "UNKNOWN_SNA" ;
VAL_ 921 DAS_suppressSpeedWarning 1 "Suppress_Speed_Warning" 0 "Do_Not_Suppress" ;
VAL_ 921 DAS_fusedSpeedLimit 31 "NONE" 0 "UNKNOWN_SNA" ;
VAL_ 921 DAS_blindSpotRearRight 3 "SNA" 0 "NO_WARNING" 1 "WARNING_LEVEL_1" 2 "WARNING_LEVEL_2" ;
VAL_ 921 DAS_blindSpotRearLeft 3 "SNA" 0 "NO_WARNING" 1 "WARNING_LEVEL_1" 2 "WARNING_LEVEL_2" ;
VAL_ 921 DAS_autopilotState 15 "SNA" 8 "ABORTING" 3 "ACTIVE_NOMINAL" 0 "DISABLED" 4 "ACTIVE_RESTRICTED" 5 "ACTIVE_NAV" 14 "FAULT" 1 "UNAVAILABLE" 9 "ABORTED" 2 "AVAILABLE" ;
VAL_ 585 SCCM_turnIndicatorStalkStatus 3 "DOWN_1" 5 "SNA" 0 "IDLE" 1 "UP_1" 4 "DOWN_2" 2 "UP_2" ;
VAL_ 585 SCCM_washWipeButtonStatus 3 "SNA" 0 "NOT_PRESSED" 2 "2ND_DETENT" 1 "1ST_DETENT" ;
VAL_ 585 SCCM_highBeamStalkStatus 3 "SNA" 0 "IDLE" 1 "PULL" 2 "PUSH" ;
VAL_ 280 DI_trackModeState 0 "TRACK_MODE_UNAVAILABLE" 1 "TRACK_MODE_AVAILABLE" 2 "TRACK_MODE_ON" ;
VAL_ 280 DI_keepAliveRequest 1 "KEEP_ALIVE" 0 "NO_REQUEST" ;
VAL_ 280 DI_epbRequest 0 "DI_EPBREQUEST_NO_REQUEST" 1 "DI_EPBREQUEST_PARK" 2 "DI_EPBREQUEST_UNPARK" ;
VAL_ 280 DI_tractionControlMode 0 "TC_NORMAL" 1 "TC_SLIP_START" 4 "TC_ROLLS_MODE" 2 "TC_DEV_MODE_1" 5 "TC_DYNO_MODE" 3 "TC_DEV_MODE_2" ;
VAL_ 280 DI_accelPedalPos 255 "SNA" ;
VAL_ 280 DI_immobilizerState 2 "DI_IMM_STATE_AUTHENTICATING" 0 "DI_IMM_STATE_INIT_SNA" 3 "DI_IMM_STATE_DISARMED" 4 "DI_IMM_STATE_IDLE" 6 "DI_IMM_STATE_FAULT" 1 "DI_IMM_STATE_REQUEST" 5 "DI_IMM_STATE_RESET" ;
VAL_ 280 DI_gear 1 "DI_GEAR_P" 0 "DI_GEAR_INVALID" 7 "DI_GEAR_SNA" 2 "DI_GEAR_R" 3 "DI_GEAR_N" 4 "DI_GEAR_D" ;
VAL_ 280 DI_brakePedalState 2 "INVALID" 0 "OFF" 1 "ON" ;
VAL_ 280 DI_systemState 5 "DI_SYS_ENABLE" 1 "DI_SYS_IDLE" 2 "DI_SYS_STANDBY" 0 "DI_SYS_UNAVAILABLE" 3 "DI_SYS_FAULT" 4 "DI_SYS_ABORT" ;
VAL_ 697 DAS_accelMax 511 "SNA" ;
VAL_ 697 DAS_accelMin 511 "SNA" ;
VAL_ 697 DAS_jerkMax 255 "SNA" ;
VAL_ 697 DAS_jerkMin 511 "SNA" ;
VAL_ 697 DAS_aebEvent 2 "AEB_FAULT" 0 "AEB_NOT_ACTIVE" 3 "AEB_SNA" 1 "AEB_ACTIVE" ;
VAL_ 697 DAS_accState 4 "ACC_ON" 9 "APC_PAUSE" 14 "ACC_CANCEL_OUT_OF_CALIBRATION" 10 "APC_UNPARK_COMPLETE" 6 "APC_FORWARD" 3 "ACC_HOLD" 2 "ACC_CANCEL_RADAR_BLIND" 7 "APC_COMPLETE" 1 "ACC_CANCEL_CAMERA_BLIND" 8 "APC_ABORT" 13 "ACC_CANCEL_GENERIC_SILENT" 5 "APC_BACKWARD" 11 "APC_SELFPARK_START" 0 "ACC_CANCEL_GENERIC" 12 "ACC_CANCEL_PATH_NOT_CLEAR" 15 "FAULT_SNA" ;
VAL_ 697 DAS_setSpeed 4095 "SNA" ;
VAL_ 341 ESP_vehicleSpeed 1023 "ESP_VEHICLE_SPEED_SNA" ;
VAL_ 341 ESP_vehicleStandstillSts 1 "STANDSTILL" 0 "NOT_STANDSTILL" ;
VAL_ 341 ESP_wheelSpeedsQF 0 "ONE_OR_MORE_WSS_INVALID" 1 "ALL_WSS_VALID" ;
VAL_ 341 ESP_WheelRotationFrL 1 "WR_BACKWARD" 0 "WR_FORWARD" 3 "WR_NOT_DEFINABLE" 2 "WR_STANDSTILL" ;
VAL_ 341 ESP_WheelRotationFrR 1 "WR_BACKWARD" 0 "WR_FORWARD" 3 "WR_NOT_DEFINABLE" 2 "WR_STANDSTILL" ;
VAL_ 341 ESP_WheelRotationReL 1 "WR_BACKWARD" 0 "WR_FORWARD" 3 "WR_NOT_DEFINABLE" 2 "WR_STANDSTILL" ;
VAL_ 341 ESP_WheelRotationReR 1 "WR_BACKWARD" 0 "WR_FORWARD" 3 "WR_NOT_DEFINABLE" 2 "WR_STANDSTILL" ;
VAL_ 341 ESP_wheelPulseCountReR 255 "SNA" ;
VAL_ 341 ESP_wheelPulseCountReL 255 "SNA" ;
VAL_ 341 ESP_wheelPulseCountFrR 255 "SNA" ;
VAL_ 341 ESP_wheelPulseCountFrL 255 "SNA" ;
VAL_ 969 APS_apbGpioState 0 "AP_GPIO_STATE_PWR_DOWN_REBOOT" 3 "AP_GPIO_STATE_HEALTHY" 1 "AP_GPIO_STATE_DISABLED" 2 "AP_GPIO_STATE_CRITICAL" ;
VAL_ 969 APS_apbStatusMonitorState 1 "STATUS_MONITOR_STATE_PWR_OFF" 2 "STATUS_MONITOR_STATE_INIT" 7 "STATUS_MONITOR_NUM_STATES" 0 "STATUS_MONITOR_STATE_UNKNOWN" 4 "STATUS_MONITOR_STATE_CRITICAL" 6 "STATUS_MONITOR_STATE_RECOVERY" 5 "STATUS_MONITOR_STATE_SHUTTING_DOWN" 3 "STATUS_MONITOR_STATE_NOMINAL" ;
VAL_ 969 APS_eacInternalState 1 "APS_EAC_STATE_MOMENTARY" 3 "APS_EAC_STATE_AUTOPARK" 5 "APS_EAC_STATE_OVERRIDE" 4 "APS_EAC_STATE_INHIBIT" 0 "APS_EAC_STATE_INIT" 2 "APS_EAC_STATE_CONTINUOUS" 7 "APS_EAC_NUM_STATES" 6 "APS_EAC_STATE_LSS" ;
VAL_ 969 APS_appGpioState 0 "AP_GPIO_STATE_PWR_DOWN_REBOOT" 3 "AP_GPIO_STATE_HEALTHY" 1 "AP_GPIO_STATE_DISABLED" 2 "AP_GPIO_STATE_CRITICAL" ;
VAL_ 969 APS_canMaster 0 "CAN_MASTER_APS" 2 "CAN_MASTER_APB" 3 "CAN_MASTER_SNA" 1 "CAN_MASTER_APP" ;
VAL_ 969 APS_vehBehaviorState 0 "VEH_BEHAVIOR_STATE_UNKNOWN" 3 "VEH_BEHAVIOR_STATE_APS_BRIDGE_APP" 1 "VEH_BEHAVIOR_STATE_APS_AVAILABLE" 5 "VEH_BEHAVIOR_STATE_APS_FAIL_SAFE" 7 "VEH_BEHAVIOR_NUM_STATES" 2 "VEH_BEHAVIOR_STATE_APS_CONTROL" 6 "VEH_BEHAVIOR_STATE_APS_OVERRIDE" 4 "VEH_BEHAVIOR_STATE_APS_BRIDGE_APB" ;
VAL_ 969 APS_appStatusMonitorState 1 "STATUS_MONITOR_STATE_PWR_OFF" 2 "STATUS_MONITOR_STATE_INIT" 7 "STATUS_MONITOR_NUM_STATES" 0 "STATUS_MONITOR_STATE_UNKNOWN" 4 "STATUS_MONITOR_STATE_CRITICAL" 6 "STATUS_MONITOR_STATE_RECOVERY" 5 "STATUS_MONITOR_STATE_SHUTTING_DOWN" 3 "STATUS_MONITOR_STATE_NOMINAL" ;
VAL_ 737 VCFRONT_homelinkCommStatus 1 "HOMELINK_COMM_STATUS_OFF" 3 "HOMELINK_COMM_STATUS_FAULT" 2 "HOMELINK_COMM_STATUS_ON" 0 "HOMELINK_COMM_STATUS_SNA" ;
VAL_ 737 VCFRONT_pressureRefrigDischarge 255 "SNA" ;
VAL_ 737 VCFRONT_pressureRefrigSuction 127 "SNA" ;
VAL_ 737 VCFRONT_airCompressorStatus 5 "VCFRONT_AIR_COMPRESSOR_STATUS_RETRY_AVAILABLE" 3 "VCFRONT_AIR_COMPRESSOR_STATUS_TURNING_ON" 4 "VCFRONT_AIR_COMPRESSOR_STATUS_FAULT" 2 "VCFRONT_AIR_COMPRESSOR_STATUS_TURNING_OFF" 7 "VCFRONT_AIR_COMPRESSOR_STATUS_SNA" 1 "VCFRONT_AIR_COMPRESSOR_STATUS_ON" 0 "VCFRONT_AIR_COMPRESSOR_STATUS_OFF" ;
VAL_ 737 VCFRONT_AS8510Voltage 4095 "SNA" ;
VAL_ 737 VCFRONT_crashState 2 "CRASH_STATE_SEVERE" 0 "CRASH_STATE_IDLE" 1 "CRASH_STATE_MINOR" ;
VAL_ 737 VCFRONT_batterySMState 2 "BATTERY_SM_STATE_DISCHARGE" 7 "BATTERY_SM_STATE_FAULT" 0 "BATTERY_SM_STATE_INIT" 3 "BATTERY_SM_STATE_STANDBY" 4 "BATTERY_SM_STATE_RESISTANCE_ESTIMATION" 5 "BATTERY_SM_STATE_OTA_STANDBY" 6 "BATTERY_SM_STATE_DISCONNECTED_BATTERY_TEST" 1 "BATTERY_SM_STATE_CHARGE" ;
VAL_ 737 VCFRONT_crashDetectedType 1 "CRASH_DETECTED_TYPE_MINOR" 0 "CRASH_DETECTED_TYPE_NONE" 2 "CRASH_DETECTED_TYPE_SEVERE" ;
VAL_ 737 VCFRONT_vehicleStatusDBG 5 "VEHICLE_STATUS_SLEEP_SHUTDOWN" 12 "VEHICLE_STATUS_CONDITIONING" 9 "VEHICLE_STATUS_HV_UP_STANDBY" 13 "VEHICLE_STATUS_DRIVE" 6 "VEHICLE_STATUS_SLEEP_STANDBY" 4 "VEHICLE_STATUS_SYSTEM_CHECKS" 10 "VEHICLE_STATUS_ACCESSORY" 14 "VEHICLE_STATUS_CRASH" 2 "VEHICLE_STATUS_SILENT_WAKE" 16 "VEHICLE_STATUS_TURN_ON_RAILS" 1 "VEHICLE_STATUS_LOW_POWER_STANDBY" 8 "VEHICLE_STATUS_LV_AWAKE" 0 "VEHICLE_STATUS_INIT" 15 "VEHICLE_STATUS_OTA" 3 "VEHICLE_STATUS_BATTERY_POST_WAKE" 7 "VEHICLE_STATUS_LV_SHUTDOWN" 17 "VEHICLE_STATUS_RESET" 11 "VEHICLE_STATUS_ACCESSORY_PLUS" ;
VAL_ 737 VCFRONT_wiperState 2 "WIPER_STATE_FAULT" 12 "WIPER_STATE_INT_AUTO_HIGH" 9 "WIPER_STATE_CONT_FAST" 8 "WIPER_STATE_INTERMITTENT_LOW" 7 "WIPER_STATE_INTERMITTENT_HIGH" 0 "WIPER_STATE_SNA" 3 "WIPER_STATE_DELAYED_REST" 10 "WIPER_STATE_CONT_SLOW" 6 "WIPER_STATE_MOMENTARY_WIPE" 1 "WIPER_STATE_SERVICE" 5 "WIPER_STATE_WASH" 4 "WIPER_STATE_PARK" 11 "WIPER_STATE_INT_AUTO_LOW" ;
VAL_ 737 VCFRONT_vbatMonitorVoltage 4095 "SNA" ;
VAL_ 737 VCFRONT_iBoosterStateDBG 3 "IBOOSTER_WRITING_DATA_SHUTDOWN" 1 "IBOOSTER_ON" 0 "IBOOSTER_OFF" 4 "IBOOSTER_FORCE_OFF" 2 "IBOOSTER_GOING_DOWN" ;
VAL_ 737 VCFRONT_wiperPosition 0 "WIPER_POSITION_SNA" 1 "WIPER_POSITION_SERVICE" 2 "WIPER_POSITION_DEPRESSED_PARK" 3 "WIPER_POSITION_DELAYED_REST" 4 "WIPER_POSITION_WIPING" ;
VAL_ 737 VCFRONT_wiperSpeed 2 "WIPER_SPEED_1" 0 "WIPER_SPEED_SNA" 7 "WIPER_SPEED_LOW" 8 "WIPER_SPEED_HIGH" 3 "WIPER_SPEED_2" 5 "WIPER_SPEED_4" 4 "WIPER_SPEED_3" 6 "WIPER_SPEED_5" 1 "WIPER_SPEED_OFF" ;
VAL_ 737 VCFRONT_frunkLatchStatus 8 "LATCH_FAULT" 2 "LATCH_CLOSED" 1 "LATCH_OPENED" 3 "LATCH_CLOSING" 7 "LATCH_DEFAULT" 4 "LATCH_OPENING" 5 "LATCH_AJAR" 6 "LATCH_TIMEOUT" 0 "LATCH_SNA" ;
VAL_ 737 VCFRONT_statusIndex 5 "VCF_STS_IDX_INVALID" 4 "VCF_STS_IDX_LV_BATTERY_DEBUG" 0 "VCF_STS_IDX_BODY_CONTROLS" 3 "VCF_STS_IDX_REFRIGERANT_SYSTEM" 2 "VCF_STS_IDX_HOMELINK" 1 "VCF_STS_IDX_VEHICLE_AND_RAILS" ;
VAL_ 925 IBST_internalState 5 "TRANSITION_TO_IDLE" 0 "NO_MODE_ACTIVE" 4 "DIAGNOSTIC" 6 "POST_DRIVE_CHECK" 1 "PRE_DRIVE_CHECK" 3 "EXTERNAL_BRAKE_REQUEST" 2 "LOCAL_BRAKE_REQUEST" ;
VAL_ 925 IBST_driverBrakeApply 1 "BRAKES_NOT_APPLIED" 2 "DRIVER_APPLYING_BRAKES" 3 "FAULT" 0 "NOT_INIT_OR_OFF" ;
VAL_ 925 IBST_iBoosterStatus 6 "IBOOSTER_ACTUATION" 4 "IBOOSTER_ACTIVE_GOOD_CHECK" 2 "IBOOSTER_FAILURE" 5 "IBOOSTER_READY" 3 "IBOOSTER_DIAGNOSTIC" 0 "IBOOSTER_OFF" 1 "IBOOSTER_INIT" ;
VAL_ 599 DI_uiSpeedUnits 0 "DI_SPEED_MPH" 1 "DI_SPEED_KPH" ;
VAL_ 599 DI_uiSpeed 255 "DI_UI_SPEED_SNA" ;
VAL_ 599 DI_vehicleSpeed 4095 "SNA" ;
VAL_ 1160 DAS_steeringControlType 2 "LANE_KEEP_ASSIST" 0 "NONE" 1 "ANGLE_CONTROL" 3 "EMERGENCY_LANE_KEEP" ;
VAL_ 1160 DAS_steeringAngleRequest 16384 "ZERO_ANGLE" ;
VAL_ 297 SCCM_steeringAngleValidity 3 "SNA" 2 "INIT" 0 "INVALID" 1 "VALID" ;
VAL_ 297 SCCM_steeringAngleSensorStatus 0 "OK" 1 "INIT" 2 "ERROR" 3 "ERROR_INIT" ;
VAL_ 82 EPAS3P_eacStatus 7 "SNA" 2 "EAC_ACTIVE" 4 "LANE_KEEP_ASSIST" 3 "EAC_FAULT" 1 "EAC_AVAILABLE" 5 "EMERGENCY_LANE_KEEP" 0 "EAC_INHIBITED" ;
VAL_ 82 EPAS3P_handsOnLevel 1 "LEVEL_1" 0 "LEVEL_0" 3 "LEVEL_3" 2 "LEVEL_2" ;
VAL_ 82 EPAS3P_torsionBarTorque 4095 "SNA" 4094 "UNDEFINABLE_DATA" ;
VAL_ 82 EPAS3P_eacErrorCode 15 "SNA" 11 "EAC_ERROR_HIGH_TORSION_SAFETY" 4 "EAC_ERROR_TMP_FAULT" 2 "EAC_ERROR_MAX_SPEED" 7 "EAC_ERROR_HIGH_ANGLE_RATE_REQ" 0 "EAC_ERROR_IDLE" 10 "EAC_ERROR_HIGH_MMOT_SAFETY" 6 "EAC_ERROR_HIGH_ANGLE_REQ" 8 "EAC_ERROR_HIGH_ANGLE_SAFETY" 5 "EAR_ERROR_MAX_STEER_DELTA" 13 "EAC_ERROR_PINION_VEL_DIFF" 1 "EAC_ERROR_MIN_SPEED" 14 "EAC_EXTERNAL_MONITOR_INHIBIT" 12 "EAC_ERROR_LOW_ASSIST" 9 "EAC_ERROR_HIGH_ANGLE_RATE_SAFETY" 3 "EAC_ERROR_HANDS_ON" ;
VAL_ 82 EPAS3P_steeringRackForce 1023 "SNA" 1022 "NOT_IN_SPEC" ;
VAL_ 82 EPAS3P_steeringFault 0 "NO_FAULT" 1 "FAULT" ;
VAL_ 82 EPAS3P_steeringReduced 0 "NORMAL_ASSIST" 1 "REDUCED_ASSIST" ;
VAL_ 82 EPAS3P_internalSASQF 1 "IN_SPEC" 0 "UNDEFINABLE_ACCURACY" ;
VAL_ 82 EPAS3P_currentTuneMode 3 "STEERING_TUNE_RWD_COMFORT" 1 "STEERING_TUNE_DM_STANDARD" 5 "STEERING_TUNE_RWD_SPORT" 0 "STEERING_TUNE_DM_COMFORT" 4 "STEERING_TUNE_RWD_STANDARD" 2 "STEERING_TUNE_DM_SPORT" ;
VAL_ 1001 DAS_turnIndicatorRequestReason 8 "DAS_ACTIVE_COMMANDED_LANE_CHANGE" 4 "DAS_CANCEL_LANE_CHANGE" 6 "DAS_ACTIVE_MERGE" 2 "DAS_ACTIVE_SPEED_LANE_CHANGE" 5 "DAS_CANCEL_FORK" 0 "DAS_NONE" 3 "DAS_ACTIVE_FORK" 7 "DAS_CANCEL_MERGE" 1 "DAS_ACTIVE_NAV_LANE_CHANGE" ;
VAL_ 1001 DAS_heaterRequest 0 "DAS_HEATER_SNA" 2 "DAS_HEATER_ON" 1 "DAS_HEATER_OFF" ;
VAL_ 1001 DAS_highLowBeamDecision 2 "DAS_HIGH_BEAM_ON" 1 "DAS_HIGH_BEAM_OFF" 3 "DAS_HIGH_BEAM_SNA" 0 "DAS_HIGH_BEAM_UNDECIDED" ;
VAL_ 1001 DAS_turnIndicatorRequest 0 "DAS_TURN_INDICATOR_NONE" 2 "DAS_TURN_INDICATOR_RIGHT" 3 "DAS_TURN_INDICATOR_CANCEL" 1 "DAS_TURN_INDICATOR_LEFT" ;
VAL_ 1001 DAS_wiperSpeed 3 "DAS_WIPER_SPEED_3" 12 "DAS_WIPER_SPEED_12" 8 "DAS_WIPER_SPEED_8" 14 "DAS_WIPER_SPEED_14" 5 "DAS_WIPER_SPEED_5" 13 "DAS_WIPER_SPEED_13" 2 "DAS_WIPER_SPEED_2" 0 "DAS_WIPER_SPEED_OFF" 4 "DAS_WIPER_SPEED_4" 1 "DAS_WIPER_SPEED_1" 15 "DAS_WIPER_SPEED_INVALID" 10 "DAS_WIPER_SPEED_10" 11 "DAS_WIPER_SPEED_11" 7 "DAS_WIPER_SPEED_7" 9 "DAS_WIPER_SPEED_9" 6 "DAS_WIPER_SPEED_6" ;
VAL_ 1001 DAS_hazardLightRequest 3 "DAS_REQUEST_HAZARDS_SNA" 2 "DAS_REQUEST_HAZARDS_UNUSED" 0 "DAS_REQUEST_HAZARDS_OFF" 1 "DAS_REQUEST_HAZARDS_ON" ;
VAL_ 1001 DAS_headlightRequest 3 "DAS_HEADLIGHT_REQUEST_INVALID" 1 "DAS_HEADLIGHT_REQUEST_ON" 0 "DAS_HEADLIGHT_REQUEST_OFF" ;
VAL_ 1013 VCFRONT_simLatchingStalk 0 "SIMULATED_LATCHING_STALK_IDLE" 1 "SIMULATED_LATCHING_STALK_LEFT" 2 "SIMULATED_LATCHING_STALK_RIGHT" 3 "SIMULATED_LATCHING_STALK_SNA" ;
VAL_ 1013 VCFRONT_parkRightStatus 2 "LIGHT_FAULT" 0 "LIGHT_OFF" 1 "LIGHT_ON" 3 "LIGHT_SNA" ;
VAL_ 1013 VCFRONT_parkLeftStatus 2 "LIGHT_FAULT" 0 "LIGHT_OFF" 1 "LIGHT_ON" 3 "LIGHT_SNA" ;
VAL_ 1013 VCFRONT_turnSignalRightStatus 2 "LIGHT_FAULT" 0 "LIGHT_OFF" 1 "LIGHT_ON" 3 "LIGHT_SNA" ;
VAL_ 1013 VCFRONT_turnSignalLeftStatus 2 "LIGHT_FAULT" 0 "LIGHT_OFF" 1 "LIGHT_ON" 3 "LIGHT_SNA" ;
VAL_ 1013 VCFRONT_sideRepeaterRightStatus 2 "LIGHT_FAULT" 0 "LIGHT_OFF" 1 "LIGHT_ON" 3 "LIGHT_SNA" ;
VAL_ 1013 VCFRONT_sideRepeaterLeftStatus 2 "LIGHT_FAULT" 0 "LIGHT_OFF" 1 "LIGHT_ON" 3 "LIGHT_SNA" ;
VAL_ 1013 VCFRONT_sideMarkersStatus 2 "LIGHT_FAULT" 0 "LIGHT_OFF" 1 "LIGHT_ON" 3 "LIGHT_SNA" ;
VAL_ 1013 VCFRONT_fogRightStatus 2 "LIGHT_FAULT" 0 "LIGHT_OFF" 1 "LIGHT_ON" 3 "LIGHT_SNA" ;
VAL_ 1013 VCFRONT_fogLeftStatus 2 "LIGHT_FAULT" 0 "LIGHT_OFF" 1 "LIGHT_ON" 3 "LIGHT_SNA" ;
VAL_ 1013 VCFRONT_DRLRightStatus 2 "LIGHT_FAULT" 0 "LIGHT_OFF" 1 "LIGHT_ON" 3 "LIGHT_SNA" ;
VAL_ 1013 VCFRONT_DRLLeftStatus 2 "LIGHT_FAULT" 0 "LIGHT_OFF" 1 "LIGHT_ON" 3 "LIGHT_SNA" ;
VAL_ 1013 VCFRONT_highBeamRightStatus 2 "LIGHT_FAULT" 0 "LIGHT_OFF" 1 "LIGHT_ON" 3 "LIGHT_SNA" ;
VAL_ 1013 VCFRONT_highBeamLeftStatus 2 "LIGHT_FAULT" 0 "LIGHT_OFF" 1 "LIGHT_ON" 3 "LIGHT_SNA" ;
VAL_ 1013 VCFRONT_lowBeamRightStatus 2 "LIGHT_FAULT" 0 "LIGHT_OFF" 1 "LIGHT_ON" 3 "LIGHT_SNA" ;
VAL_ 1013 VCFRONT_lowBeamLeftStatus 2 "LIGHT_FAULT" 0 "LIGHT_OFF" 1 "LIGHT_ON" 3 "LIGHT_SNA" ;
VAL_ 1013 VCFRONT_switchLightingBrightness 255 "SNA" ;
VAL_ 1013 VCFRONT_ambientLightingBrightnes 255 "SNA" ;
VAL_ 1013 VCFRONT_hazardLightRequest 1 "HAZARD_REQUEST_BUTTON" 6 "HAZARD_REQUEST_CAR_ALARM" 5 "HAZARD_REQUEST_CRASH" 7 "HAZARD_REQUEST_DAS" 2 "HAZARD_REQUEST_LOCK" 4 "HAZARD_REQUEST_MISLOCK" 0 "HAZARD_REQUEST_NONE" 8 "HAZARD_REQUEST_UDS" 3 "HAZARD_REQUEST_UNLOCK" ;
VAL_ 1013 VCFRONT_indicatorRightRequest 2 "TURN_SIGNAL_ACTIVE_HIGH" 1 "TURN_SIGNAL_ACTIVE_LOW" 0 "TURN_SIGNAL_OFF" ;
VAL_ 1013 VCFRONT_indicatorLeftRequest 2 "TURN_SIGNAL_ACTIVE_HIGH" 1 "TURN_SIGNAL_ACTIVE_LOW" 0 "TURN_SIGNAL_OFF" ;
